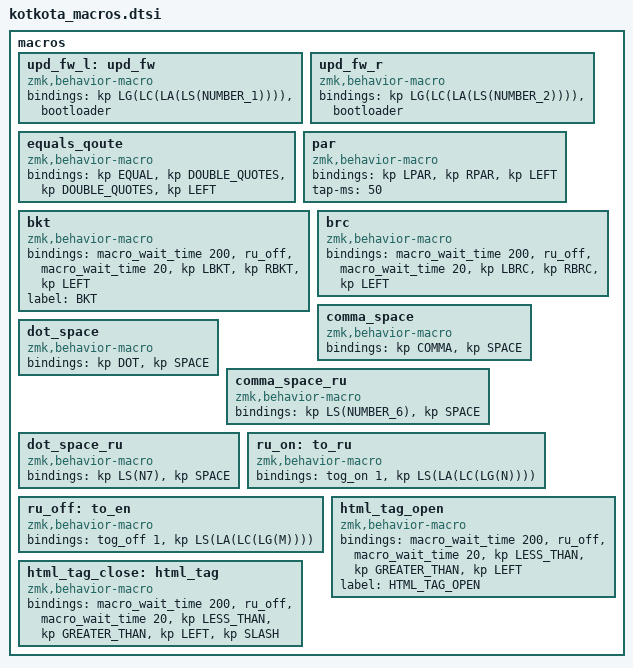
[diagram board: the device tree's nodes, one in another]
macros {
  upd_fw_l: upd_fw {
    compatible = "zmk,behavior-macro";
    #binding-cells = <0>;
    bindings = <&kp LG(LC(LA(LS(NUMBER_1)))) &bootloader>;
  };

  upd_fw_r: upd_fw_r {
    compatible = "zmk,behavior-macro";
    #binding-cells = <0>;
    bindings = <&kp LG(LC(LA(LS(NUMBER_2)))) &bootloader>;
  };

  equals_qoute: equals_qoute {
    compatible = "zmk,behavior-macro";
    #binding-cells = <0>;
    bindings = <&kp EQUAL &kp DOUBLE_QUOTES &kp DOUBLE_QUOTES &kp LEFT>;
  };

  par: par {
    compatible = "zmk,behavior-macro";
    #binding-cells = <0>;
    bindings = <&kp LPAR &kp RPAR &kp LEFT>;
    tap-ms = <50>;
  };

  bkt: bkt {
    compatible = "zmk,behavior-macro";
    #binding-cells = <0>;
    bindings =
      <&macro_wait_time 200>,
      <&ru_off>,
      <&macro_wait_time 20>,
      <&kp LBKT &kp RBKT &kp LEFT>;

    label = "BKT";
  };

  brc: brc {
    compatible = "zmk,behavior-macro";
    #binding-cells = <0>;
    bindings =
      <&macro_wait_time 200>,
      <&ru_off>,
      <&macro_wait_time 20>,
      <&kp LBRC &kp RBRC &kp LEFT>;
  };

  comma_space: comma_space {
    compatible = "zmk,behavior-macro";
    #binding-cells = <0>;
    bindings = <&kp COMMA &kp SPACE>;
  };

  dot_space: dot_space {
    compatible = "zmk,behavior-macro";
    #binding-cells = <0>;
    bindings = <&kp DOT &kp SPACE>;
  };

  comma_space_ru: comma_space_ru {
    compatible = "zmk,behavior-macro";
    #binding-cells = <0>;
    bindings = <&kp LS(NUMBER_6) &kp SPACE>;
  };

  dot_space_ru: dot_space_ru {
    compatible = "zmk,behavior-macro";
    #binding-cells = <0>;
    bindings = <&kp LS(N7) &kp SPACE>;
  };

  ru_on: to_ru {
    compatible = "zmk,behavior-macro";
    #binding-cells = <0>;
    bindings = <&tog_on 1 &kp LS(LA(LC(LG(N))))>;
  };

  ru_off: to_en {
    compatible = "zmk,behavior-macro";
    #binding-cells = <0>;
    bindings = <&tog_off 1 &kp LS(LA(LC(LG(M))))>;
  };

  html_tag_open: html_tag_open {
    compatible = "zmk,behavior-macro";
    #binding-cells = <0>;
    bindings =
      <&macro_wait_time 200>,
      <&ru_off>,
      <&macro_wait_time 20>,
      <&kp LESS_THAN &kp GREATER_THAN &kp LEFT>;

    label = "HTML_TAG_OPEN";
  };

  html_tag_close: html_tag {
    compatible = "zmk,behavior-macro";
    #binding-cells = <0>;
    bindings =
      <&macro_wait_time 200>,
      <&ru_off>,
      <&macro_wait_time 20>,
      <&kp LESS_THAN &kp GREATER_THAN &kp LEFT &kp SLASH>;
  };
};
